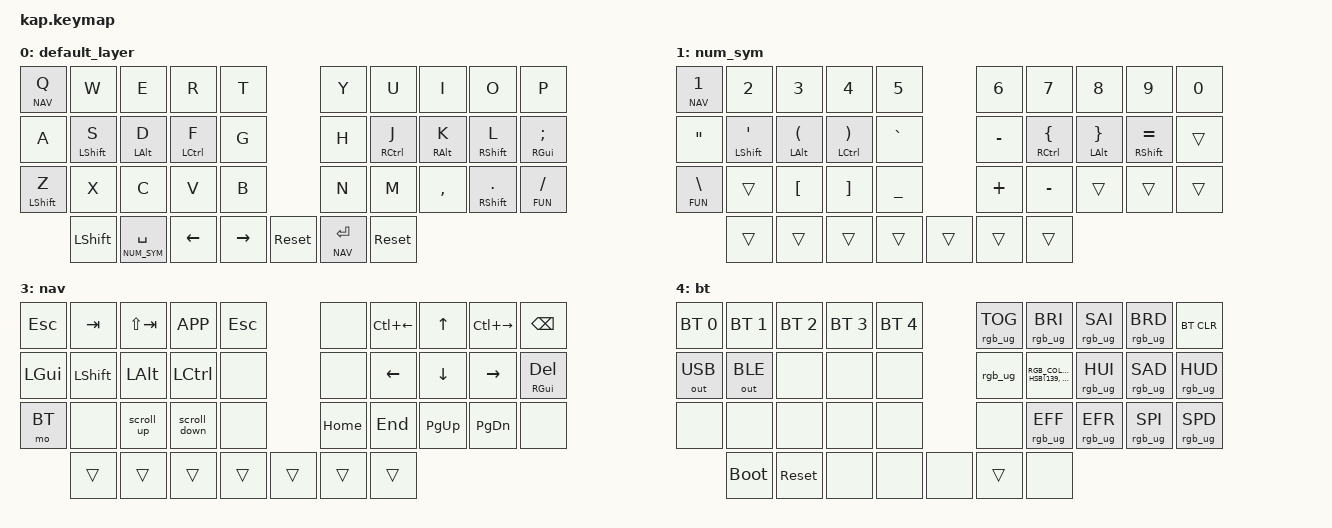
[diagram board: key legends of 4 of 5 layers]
#include <behaviors.dtsi>
#include <dt-bindings/zmk/keys.h>
#include <dt-bindings/zmk/bt.h>
#include <dt-bindings/zmk/outputs.h>
#include <dt-bindings/zmk/rgb.h>

#define DEFAULT 0
#define NUM_SYM 1
#define FUN     2
#define NAV     3
#define BT      4

#define COMBO_TIMEOUT 20
#define LONG_COMBO_TIMEOUT 100
#define TD_TIMEOUT 150
#define SHORT_TD_TIMEOUT 120
#define TAP_TIMEOUT 150

&lt {
    tapping-term-ms = <TAP_TIMEOUT>;
};

/ {
    behaviors {
        hm: homerow_mods {
            compatible = "zmk,behavior-hold-tap";
            label = "homerow mods";
            #binding-cells = <2>;
            tapping-term-ms = <TAP_TIMEOUT>;
            quick-tap-ms = <50>;
            global-quick-tap;
            flavor = "tap-preferred";
            bindings = <&kp>, <&kp>;
        };

        hmf: homerow_mods_fast {
            compatible = "zmk,behavior-hold-tap";
            label = "homerow mods fast";
            #binding-cells = <2>;
            tapping-term-ms = <90>;
            flavor = "tap-preferred";
            bindings = <&kp>, <&kp>;
        };

        tdlctrl: tap_dance_lctrl {
            compatible = "zmk,behavior-tap-dance";
            label = "TAP_DANCE_LCTRL";
            #binding-cells = <0>;
            tapping-term-ms = <TD_TIMEOUT>;
            bindings = <&kp LCTRL>, <&kp LSHFT>;
        };

        tdlalt: tap_dance_lalt {
            compatible = "zmk,behavior-tap-dance";
            label = "TAP_DANCE_LALT";
            #binding-cells = <0>;
            tapping-term-ms = <TD_TIMEOUT>;
            bindings = <&kp LALT>, <&kp LGUI>;
        };

        /*tdk: tap_dance_k {
            compatible = "zmk,behavior-tap-dance";
            label = "TAP_DANCE_K";
            #binding-cells = <0>;
            tapping-term-ms = <SHORT_TD_TIMEOUT>;
            bindings = <&hmf RALT K>;
        };*/

        enc_scroll: encoder_scroll {
            compatible = "zmk,behavior-sensor-rotate";
            label = "ENC_SCROLL";
            #sensor-binding-cells = <0>;
            bindings = <&scroll_down>, <&scroll_up>;
        };
    };
};

/ {
    combos {
        compatible = "zmk,combos";
        combo_qw_tab {
            timeout-ms = <COMBO_TIMEOUT>;
            key-positions = <0 1>;
            bindings = <&kp TAB>;
        };
        /*
        combo_we_esc {
            timeout-ms = <COMBO_TIMEOUT>;
            key-positions = <1 2>;
            bindings = <&kp ESC>;
        };
        */

        combo_io_del {
            timeout-ms = <COMBO_TIMEOUT>;
            key-positions = <7 8>;
            bindings = <&kp LC(DEL)>;
        };
        combo_op_bspc {
            timeout-ms = <COMBO_TIMEOUT>;
            key-positions = <8 9>;
            bindings = <&kp LC(BSPC)>;
        };

        combo_as_save {
            timeout-ms = <COMBO_TIMEOUT>;
            key-positions = <10 11>;
            bindings = <&kp LC(S)>;
        };

        combo_lsemi_ret {
            timeout-ms = <COMBO_TIMEOUT>;
            key-positions = <18 19>;
            bindings = <&kp RET>;
        };

        combo_zx_cut {
            timeout-ms = <COMBO_TIMEOUT>;
            key-positions = <20 21>;
            bindings = <&kp LC(X)>;
        };
        combo_xc_copy {
            timeout-ms = <COMBO_TIMEOUT>;
            key-positions = <21 22>;
            bindings = <&kp LC(C)>;
        };
        combo_cv_paste {
            timeout-ms = <COMBO_TIMEOUT>;
            key-positions = <22 23>;
            bindings = <&kp LC(V)>;
        };
        combo_cv_paste {
            timeout-ms = <COMBO_TIMEOUT>;
            key-positions = <24 25>;
            bindings = <&lt NUM_SYM SPACE>;
        };
    };
};
/ {
    keymap {
        compatible = "zmk,keymap";

        default_layer {
// --------------------------------------------------------------------------------------------------------------------------------------------------------------------
// |    Q    |    W    |    E    |    R    |    T    |                |    Y    |    U    |    I    |    O    |    P    |
// |    A    |    S    |    D    |    F    |    G    |                |    H    |    J    |    K    |    L    |    ;    |
// |    Z    |    X    |    C    |    V    |    B    |                |    N    |    M    |    ,    |    .    |    /    |
//         |   UP   |  SPACE  | LEFT  |  RIGHT  | RESET  |        |  RETURN |  RESET  |
            bindings = <
    &lt NAV Q   &kp W       &kp E       &kp R       &kp T                         &kp Y   &kp U       &kp I       &kp O         &kp P
    &kp A       &hm LSHFT S &hm LALT D  &hm LCTRL F &kp G                         &kp H   &hm RCTRL J &hm RALT K  &hm RSHFT L   &hm RGUI SEMI
    &hm LSHFT Z &kp X       &kp C       &kp V       &kp B                         &kp N   &kp M       &kp COMMA   &hm RSHFT DOT &lt FUN FSLH
                &kp LSHIFT  &lt NUM_SYM SPACE &kp LEFT &kp RIGHT &sys_reset    &lt NAV RET &sys_reset
            >;
        };
        
        num_sym {
            bindings = <
    &lt NAV N1    &kp N2        &kp N3        &kp N4         &kp N5               &kp N6    &kp N7         &kp N8        &kp N9          &kp N0
    &kp DQT       &hm LSHFT SQT &hm LALT LPAR &hm LCTRL RPAR &kp GRAVE            &kp MINUS &hm RCTRL LBRC &hm LALT RBRC &hm RSHFT EQUAL &trans
    &lt FUN BSLH  &trans        &kp LBKT      &kp RBKT       &kp UNDER            &kp PLUS  &kp MINUS      &trans        &trans          &trans
                &trans      &trans             &trans   &trans   &trans        &trans   &trans
            >;
        };
        
        fun {
            bindings = <
    &trans &trans &trans &trans &trans          &kp F1  &kp F2       &kp F3      &kp F4          &kp F5
    &trans &trans &trans &trans &trans          &kp F6  &hm RCTRL F7 &hm LALT F8 &hm RSHFT F9    &hm RGUI F10
    &trans &trans &trans &trans &trans          &kp F11 &kp F12      &kp PSCRN   &kp PAUSE_BREAK
      &trans &trans &trans &trans &trans       &trans  &none
            >;
        };

        nav {
            bindings = <
    &kp ESC  &kp TAB   &kp LS(TAB) &kp K_APP    &kp ESC         &none    &kp LC(LEFT) &kp UP    &kp LC(RIGHT) &kp BSPC
    &kp LGUI &kp LSHFT &kp LALT    &kp LCTRL    &none           &none    &kp LEFT     &kp DOWN  &kp RIGHT     &hm RGUI DEL
    &mo BT   &none     &scroll_up  &scroll_down &none           &kp HOME &kp END      &kp PG_UP &kp PG_DN     &none
      &trans   &trans    &trans      &trans       &trans        &trans   &trans
            >;
        };
 
        bt {
            bindings = <
    &bt BT_SEL 0 &bt BT_SEL 1 &bt BT_SEL 2 &bt BT_SEL 3 &bt BT_SEL 4         &rgb_ug RGB_TOG  &rgb_ug RGB_BRI &rgb_ug RGB_SAI &rgb_ug RGB_BRD &bt BT_CLR
    &out OUT_USB &out OUT_BLE &none        &none        &none                &rgb_ug RGB_COLOR_HSB(139, 100, 39)  &rgb_ug RGB_HUI &rgb_ug RGB_SAD &rgb_ug RGB_HUD &none
    &none        &none        &none        &none        &none                &rgb_ug RGB_EFF  &rgb_ug RGB_EFR &rgb_ug RGB_SPI &rgb_ug RGB_SPD
      &bootloader  &sys_reset       &none        &none        &none        &trans &none
            >;
        };

    };
};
